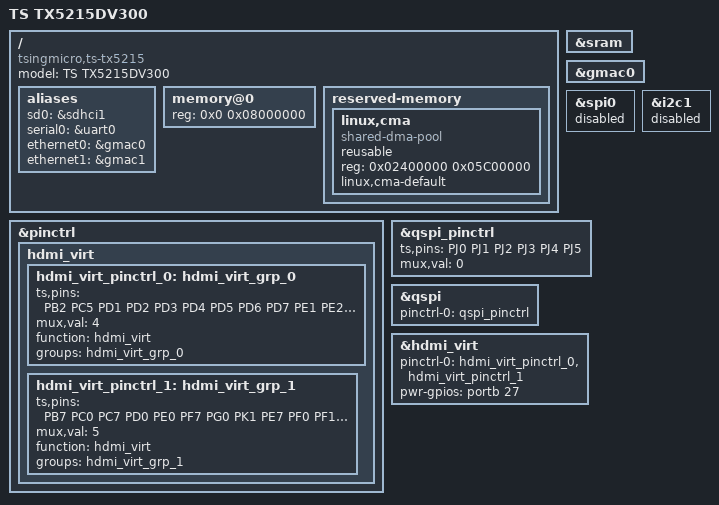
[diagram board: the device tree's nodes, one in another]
/*
 * dts file for tsingmicro tx511 haps
 *
 * Copyright 2022 Tsingmicro, Inc.
 *
 * This program is free software; you can redistribute it and/or
 * modify it under the terms of the GNU General Public License as
 * published by the Free Software Foundation; either version 2 of
 * the License, or (at your option) any later version.
 */

/dts-v1/;

#include "ts-tx52xx-evb132.dtsi"

/ {
	model = "TS TX5215DV300";
	compatible = "tsingmicro,ts-tx5215";//smp need

	aliases {
		sd0 = &sdhci1;
		serial0 = &uart0;
		ethernet0 = &gmac0;
		ethernet1 = &gmac1;
	};
	memory@0 {
		device_type = "memory";
		reg = <0x0 0x08000000>;
	};
	reserved-memory {
		#address-cells = <1>;
		#size-cells = <1>;
		ranges;
		/* global autoconfigured region for contiguous allocations */
		linux,cma {
			compatible = "shared-dma-pool";
			reusable;
			reg = <0x02400000 0x05C00000>;  //92M
			linux,cma-default;
		};

	};
};

&pinctrl {
	hdmi_virt {
		hdmi_virt_pinctrl_0:hdmi_virt_grp_0 {
			ts,pins = <PB2 PC5 PD1 PD2 PD3 PD4 PD5 PD6 PD7 PE1 PE2 PE3 PE4 PE5 PE6>;
			mux,val = <4>;
			function = "hdmi_virt";
			groups = "hdmi_virt_grp_0";
		};
		hdmi_virt_pinctrl_1: hdmi_virt_grp_1 {
			ts,pins = <PB7 PC0 PC7 PD0 PE0 PF7 PG0 PK1 PE7 PF0 PF1 PF2>;//PE7 PF0 PF1 PF2
			mux,val = <5>;
			function = "hdmi_virt";
			groups = "hdmi_virt_grp_1";
		};
	};
};

&sram {
	status = "okay";
};
&gmac0{
	status = "okay";
};

&spi0 {
	status = "disabled";
};

&i2c1 {
	status = "disabled";
};


&qspi_pinctrl {
	ts,pins = <PJ0 PJ1 PJ2 PJ3 PJ4 PJ5>;
	mux,val = <0>;
};


&qspi {
	status = "okay";
	pinctrl-names = "default";
	pinctrl-0 = <&qspi_pinctrl>;
};


&hdmi_virt {
	pinctrl-names = "default";
	pinctrl-0 = <&hdmi_virt_pinctrl_0 &hdmi_virt_pinctrl_1>;
	pwr-gpios = <&portb 27 GPIO_ACTIVE_HIGH>;	
};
